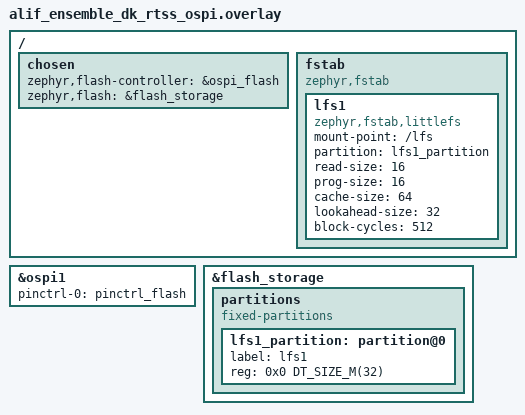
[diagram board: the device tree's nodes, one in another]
/*
 * Copyright (c) 2025 Alif Semiconductor.
 * SPDX-License-Identifier: Apache-2.0
 */

&ospi1 {
	status = "okay";
	/* pinctrl_flash is defined by the ospi-flash snippet. */
	pinctrl-0 = <&pinctrl_flash>;
};

/* Update zephyr,flash property */
/{
	chosen {
		zephyr,flash-controller = &ospi_flash;
		zephyr,flash = &flash_storage;
	};

	fstab {
		compatible = "zephyr,fstab";

		lfs1: lfs1 {
			compatible = "zephyr,fstab,littlefs";
			mount-point = "/lfs";
			partition = <&lfs1_partition>;
			read-size = <16>;
			prog-size = <16>;
			cache-size = <64>;
			lookahead-size = <32>;
			block-cycles = <512>;
		};
	};
};


/* OSPI Flash storage*/
&flash_storage {
	partitions {
		#address-cells = <1>;
		#size-cells = <1>;
		compatible = "fixed-partitions";

		/* Set 32MB of storage flash */
		lfs1_partition: partition@0 {
			label = "lfs1";
			reg = <0x0 DT_SIZE_M(32)>;
		};
	};
};
